# f28004x_erad_hwbp_registers_regs register map
Vendor: Texas Instruments
Peripheral module from a debugger description file (folder C2000).
Address unit: 16 bits
Registers are 16-bit, read-write, no defined reset value unless marked. A register's access mark holds for its fields unless they carry their own. Offsets are as the file gives them; lines under a group give offsets from that group; [hi:lo] are bit positions; {n}, {i} and the like mark numbered series; 'fields as' and 'values as' point back to an identical list; <NAME> marks a mode.

## ERAD_HWBP_REGISTERS — ERAD HWBP REGISTERS Registers
0x00 HWBP_MASK_LOW1
  [15:0] MASK_LOW — Lower 16 bits of the Address mask[[br]]register
0x01 HWBP_MASK_HIGH1
  [15:0] MASK_HIGH — Upper 16 bits of the Address mask[[br]]register
0x02 HWBP_REF_LOW1
  [15:0] REF_LOW — Lower 16 bits of the Address reference register
0x03 HWBP_REF_HIGH1
  [15:0] REF_HIGH — Higher 16 bits of the Address reference register
0x04 HWBP_CLEAR1 access not given
  [0] EVENT_CLR — Event Clear register (access R=0/W)
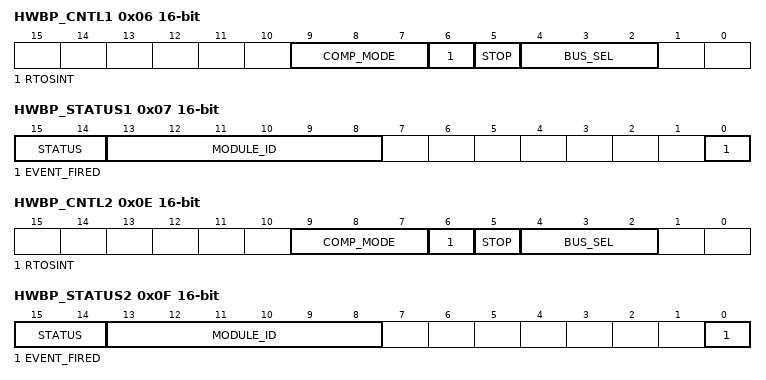
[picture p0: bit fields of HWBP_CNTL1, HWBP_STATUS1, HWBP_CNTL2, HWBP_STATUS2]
0x06 HWBP_CNTL1
  [9:7] COMP_MODE — Compare mode
  [6] RTOSINT — RTOSINT bit
  [5] STOP — Stop bit (Halt/No Halt of CPU)
  [4:2] BUS_SEL — Bus select bits
0x07 HWBP_STATUS1 ro
  [15:14] STATUS — Status bits
  [13:8] MODULE_ID — Identification bits
  [0] EVENT_FIRED — HWBP Event Fired bits
0x08 HWBP_MASK_LOW2
  [15:0] MASK_LOW — Lower 16 bits of the Address mask[[br]]register
0x09 HWBP_MASK_HIGH2
  [15:0] MASK_HIGH — Upper 16 bits of the Address mask[[br]]register
0x0A HWBP_REF_LOW2
  [15:0] REF_LOW — Lower 16 bits of the Address reference register
0x0B HWBP_REF_HIGH2
  [15:0] REF_HIGH — Higher 16 bits of the Address reference register
0x0C HWBP_CLEAR2 access not given
  [0] EVENT_CLR — Event Clear register (access R=0/W)
0x0E HWBP_CNTL2
  fields as HWBP_CNTL1
0x0F HWBP_STATUS2 ro
  fields as HWBP_STATUS1
0x10 HWBP_MASK_LOW3
  [15:0] MASK_LOW — Lower 16 bits of the Address mask[[br]]register
0x11 HWBP_MASK_HIGH3
  [15:0] MASK_HIGH — Upper 16 bits of the Address mask[[br]]register
0x12 HWBP_REF_LOW3
  [15:0] REF_LOW — Lower 16 bits of the Address reference register
0x13 HWBP_REF_HIGH3
  [15:0] REF_HIGH — Higher 16 bits of the Address reference register
0x14 HWBP_CLEAR3 access not given
  [0] EVENT_CLR — Event Clear register (access R=0/W)
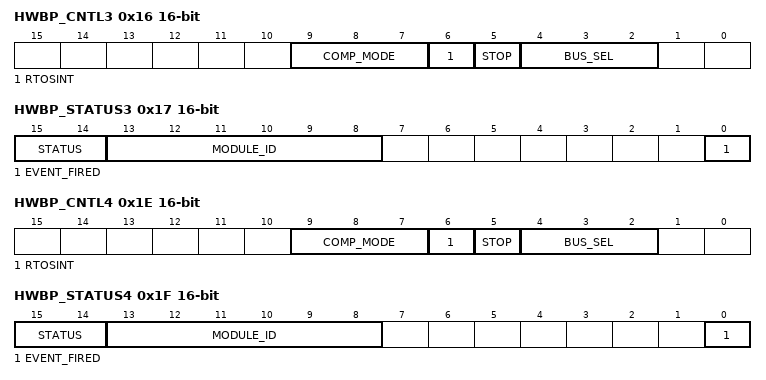
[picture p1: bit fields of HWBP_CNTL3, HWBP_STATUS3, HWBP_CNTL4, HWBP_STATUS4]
0x16 HWBP_CNTL3
  fields as HWBP_CNTL1
0x17 HWBP_STATUS3 ro
  fields as HWBP_STATUS1
0x18 HWBP_MASK_LOW4
  [15:0] MASK_LOW — Lower 16 bits of the Address mask[[br]]register
0x19 HWBP_MASK_HIGH4
  [15:0] MASK_HIGH — Upper 16 bits of the Address mask[[br]]register
0x1A HWBP_REF_LOW4
  [15:0] REF_LOW — Lower 16 bits of the Address reference register
0x1B HWBP_REF_HIGH4
  [15:0] REF_HIGH — Higher 16 bits of the Address reference register
0x1C HWBP_CLEAR4 access not given
  [0] EVENT_CLR — Event Clear register (access R=0/W)
0x1E HWBP_CNTL4
  fields as HWBP_CNTL1
0x1F HWBP_STATUS4 ro
  fields as HWBP_STATUS1
0x20 HWBP_MASK_LOW5
  [15:0] MASK_LOW — Lower 16 bits of the Address mask[[br]]register
0x21 HWBP_MASK_HIGH5
  [15:0] MASK_HIGH — Upper 16 bits of the Address mask[[br]]register
0x22 HWBP_REF_LOW5
  [15:0] REF_LOW — Lower 16 bits of the Address reference register
0x23 HWBP_REF_HIGH5
  [15:0] REF_HIGH — Higher 16 bits of the Address reference register
0x24 HWBP_CLEAR5 access not given
  [0] EVENT_CLR — Event Clear register (access R=0/W)
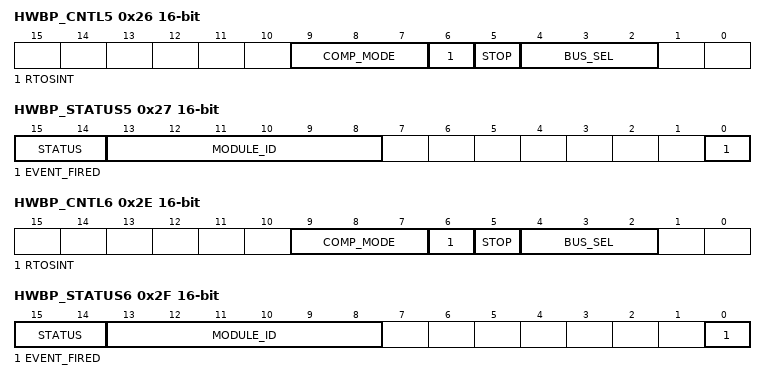
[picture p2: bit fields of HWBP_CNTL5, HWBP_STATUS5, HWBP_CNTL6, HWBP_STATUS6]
0x26 HWBP_CNTL5
  fields as HWBP_CNTL1
0x27 HWBP_STATUS5 ro
  fields as HWBP_STATUS1
0x28 HWBP_MASK_LOW6
  [15:0] MASK_LOW — Lower 16 bits of the Address mask[[br]]register
0x29 HWBP_MASK_HIGH6
  [15:0] MASK_HIGH — Upper 16 bits of the Address mask[[br]]register
0x2A HWBP_REF_LOW6
  [15:0] REF_LOW — Lower 16 bits of the Address reference register
0x2B HWBP_REF_HIGH6
  [15:0] REF_HIGH — Higher 16 bits of the Address reference register
0x2C HWBP_CLEAR6 access not given
  [0] EVENT_CLR — Event Clear register (access R=0/W)
0x2E HWBP_CNTL6
  fields as HWBP_CNTL1
0x2F HWBP_STATUS6 ro
  fields as HWBP_STATUS1
0x30 HWBP_MASK_LOW7
  [15:0] MASK_LOW — Lower 16 bits of the Address mask[[br]]register
0x31 HWBP_MASK_HIGH7
  [15:0] MASK_HIGH — Upper 16 bits of the Address mask[[br]]register
0x32 HWBP_REF_LOW7
  [15:0] REF_LOW — Lower 16 bits of the Address reference register
0x33 HWBP_REF_HIGH7
  [15:0] REF_HIGH — Higher 16 bits of the Address reference register
0x34 HWBP_CLEAR7 access not given
  [0] EVENT_CLR — Event Clear register (access R=0/W)
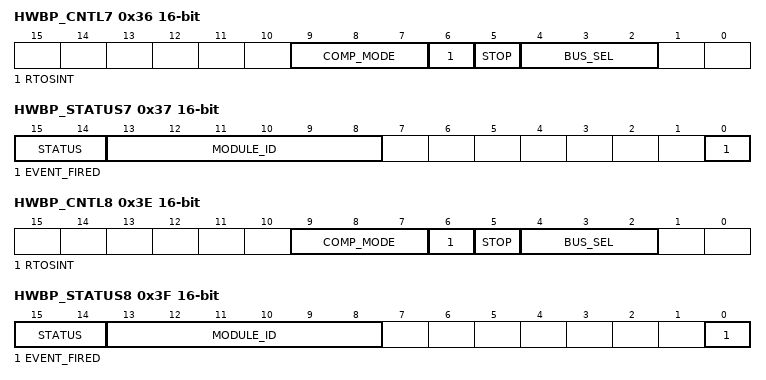
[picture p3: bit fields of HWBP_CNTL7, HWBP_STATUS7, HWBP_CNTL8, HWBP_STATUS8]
0x36 HWBP_CNTL7
  fields as HWBP_CNTL1
0x37 HWBP_STATUS7 ro
  fields as HWBP_STATUS1
0x38 HWBP_MASK_LOW8
  [15:0] MASK_LOW — Lower 16 bits of the Address mask[[br]]register
0x39 HWBP_MASK_HIGH8
  [15:0] MASK_HIGH — Upper 16 bits of the Address mask[[br]]register
0x3A HWBP_REF_LOW8
  [15:0] REF_LOW — Lower 16 bits of the Address reference register
0x3B HWBP_REF_HIGH8
  [15:0] REF_HIGH — Higher 16 bits of the Address reference register
0x3C HWBP_CLEAR8 access not given
  [0] EVENT_CLR — Event Clear register (access R=0/W)
0x3E HWBP_CNTL8
  fields as HWBP_CNTL1
0x3F HWBP_STATUS8 ro
  fields as HWBP_STATUS1
